# RP2350 register map
Vendor: Raspberry Pi; Series: RP; File version: 0.1
CPU: CM33 r1p0, little endian, MPU, FPU, DSP, VTOR, 4 interrupt priority bits, 52 interrupts, 8 SAU regions
Registers are 32-bit, read-write, reset 0x0 unless marked. A register's access mark holds for its fields unless they carry their own. Offsets are from the block's base; [hi:lo] are bit positions; {n}, {i} and the like mark numbered series; <NAME> marks a mode.

## BUSCTRL — Register block for busfabric control signals and performance counters
Base 0x40068000
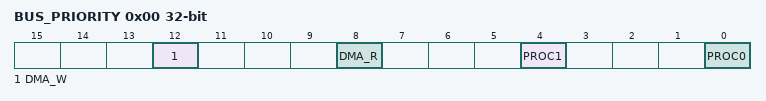
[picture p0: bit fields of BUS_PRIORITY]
0x00 BUS_PRIORITY — Set the priority of each master for bus arbitration.
  [12] DMA_W — 0 - low priority, 1 - high priority
  [8] DMA_R — 0 - low priority, 1 - high priority
  [4] PROC1 — 0 - low priority, 1 - high priority
  [0] PROC0 — 0 - low priority, 1 - high priority
0x04 BUS_PRIORITY_ACK — Bus priority acknowledge
  [0] BUS_PRIORITY_ACK ro — Goes to 1 once all arbiters have registered the new global priority levels. Arbiters update their local priority when servicing a new nonsequential access. In normal circumstances this will happen almost immediately.
0x08 PERFCTR_EN — Enable the performance counters. If 0, the performance counters do not increment. This can be used to precisely start/stop event sampling around the profiled section of code. The performance counters are initially disabled, to save energy.
  [0] PERFCTR_EN — Pre-defined description
{0xC+8i} PERFCTR{i} (i=0..3) — Bus fabric performance counter {i}
  [23:0] PERFCTR{i} write-1-clears — Busfabric saturating performance counter {i} Count some event signal from the busfabric arbiters, if PERFCTR_EN is set. Write any value to clear. Select an event to count using PERFSEL{i}
{0x10+8i} PERFSEL{i} reset 0x1F (i=0..3) — Bus fabric performance event select for PERFCTR{i}
  [6:0] PERFSEL{i} — Select an event for PERFCTR{i}. For each downstream port of the main crossbar, four events are available: ACCESS, an access took place; ACCESS_CONTESTED, an access took place that previously stalled due to contention from other masters; STALL_DOWNSTREAM, count cycles where any master stalled due to a stall on the downstream bus; STALL_UPSTREAM, count cycles where any master stalled for any reason, including contention from other masters.
    0=siob_proc1_stall_upstream; 1=siob_proc1_stall_downstream; 2=siob_proc1_access_contested; 3=siob_proc1_access; 4=siob_proc0_stall_upstream; 5=siob_proc0_stall_downstream; 6=siob_proc0_access_contested; 7=siob_proc0_access; 8=apb_stall_upstream; 9=apb_stall_downstream; 10=apb_access_contested; 11=apb_access; 12=fastperi_stall_upstream; 13=fastperi_stall_downstream; 14=fastperi_access_contested; 15=fastperi_access; 16=sram9_stall_upstream; 17=sram9_stall_downstream; 18=sram9_access_contested; 19=sram9_access; 20=sram8_stall_upstream; 21=sram8_stall_downstream; 22=sram8_access_contested; 23=sram8_access; 24=sram7_stall_upstream; 25=sram7_stall_downstream; 26=sram7_access_contested; 27=sram7_access; 28=sram6_stall_upstream; 29=sram6_stall_downstream; 30=sram6_access_contested; 31=sram6_access; 32=sram5_stall_upstream; 33=sram5_stall_downstream; 34=sram5_access_contested; 35=sram5_access; 36=sram4_stall_upstream; 37=sram4_stall_downstream; 38=sram4_access_contested; 39=sram4_access; 40=sram3_stall_upstream; 41=sram3_stall_downstream; 42=sram3_access_contested; 43=sram3_access; 44=sram2_stall_upstream; 45=sram2_stall_downstream; 46=sram2_access_contested; 47=sram2_access; 48=sram1_stall_upstream; 49=sram1_stall_downstream; 50=sram1_access_contested; 51=sram1_access; 52=sram0_stall_upstream; 53=sram0_stall_downstream; 54=sram0_access_contested; 55=sram0_access; 56=xip_main1_stall_upstream; 57=xip_main1_stall_downstream; 58=xip_main1_access_contested; 59=xip_main1_access; 60=xip_main0_stall_upstream; 61=xip_main0_stall_downstream; 62=xip_main0_access_contested; 63=xip_main0_access; 64=rom_stall_upstream; 65=rom_stall_downstream; 66=rom_access_contested; 67=rom_access

## BOOTRAM — Additional registers mapped adjacent to the bootram, for use by the bootrom.
Base 0x400E0000
0x800 WRITE_ONCE0 — This registers always ORs writes into its current contents. Once a bit is set, it can only be cleared by a reset.
  [31:0] WRITE_ONCE0 — Pre-defined description
0x804 WRITE_ONCE1 — This registers always ORs writes into its current contents. Once a bit is set, it can only be cleared by a reset.
  [31:0] WRITE_ONCE1 — Pre-defined description
0x808 BOOTLOCK_STAT reset 0xFF — Bootlock status register. 1=unclaimed, 0=claimed. These locks function identically to the SIO spinlocks, but are reserved for bootrom use.
  [7:0] BOOTLOCK_STAT — Pre-defined description
{0x80C+4i} BOOTLOCK{i} (i=0..7) — Read to claim and check. Write to unclaim. The value returned on successful claim is 1 << n, and on failed claim is zero.
  [31:0] BOOTLOCK{i} — Pre-defined description
